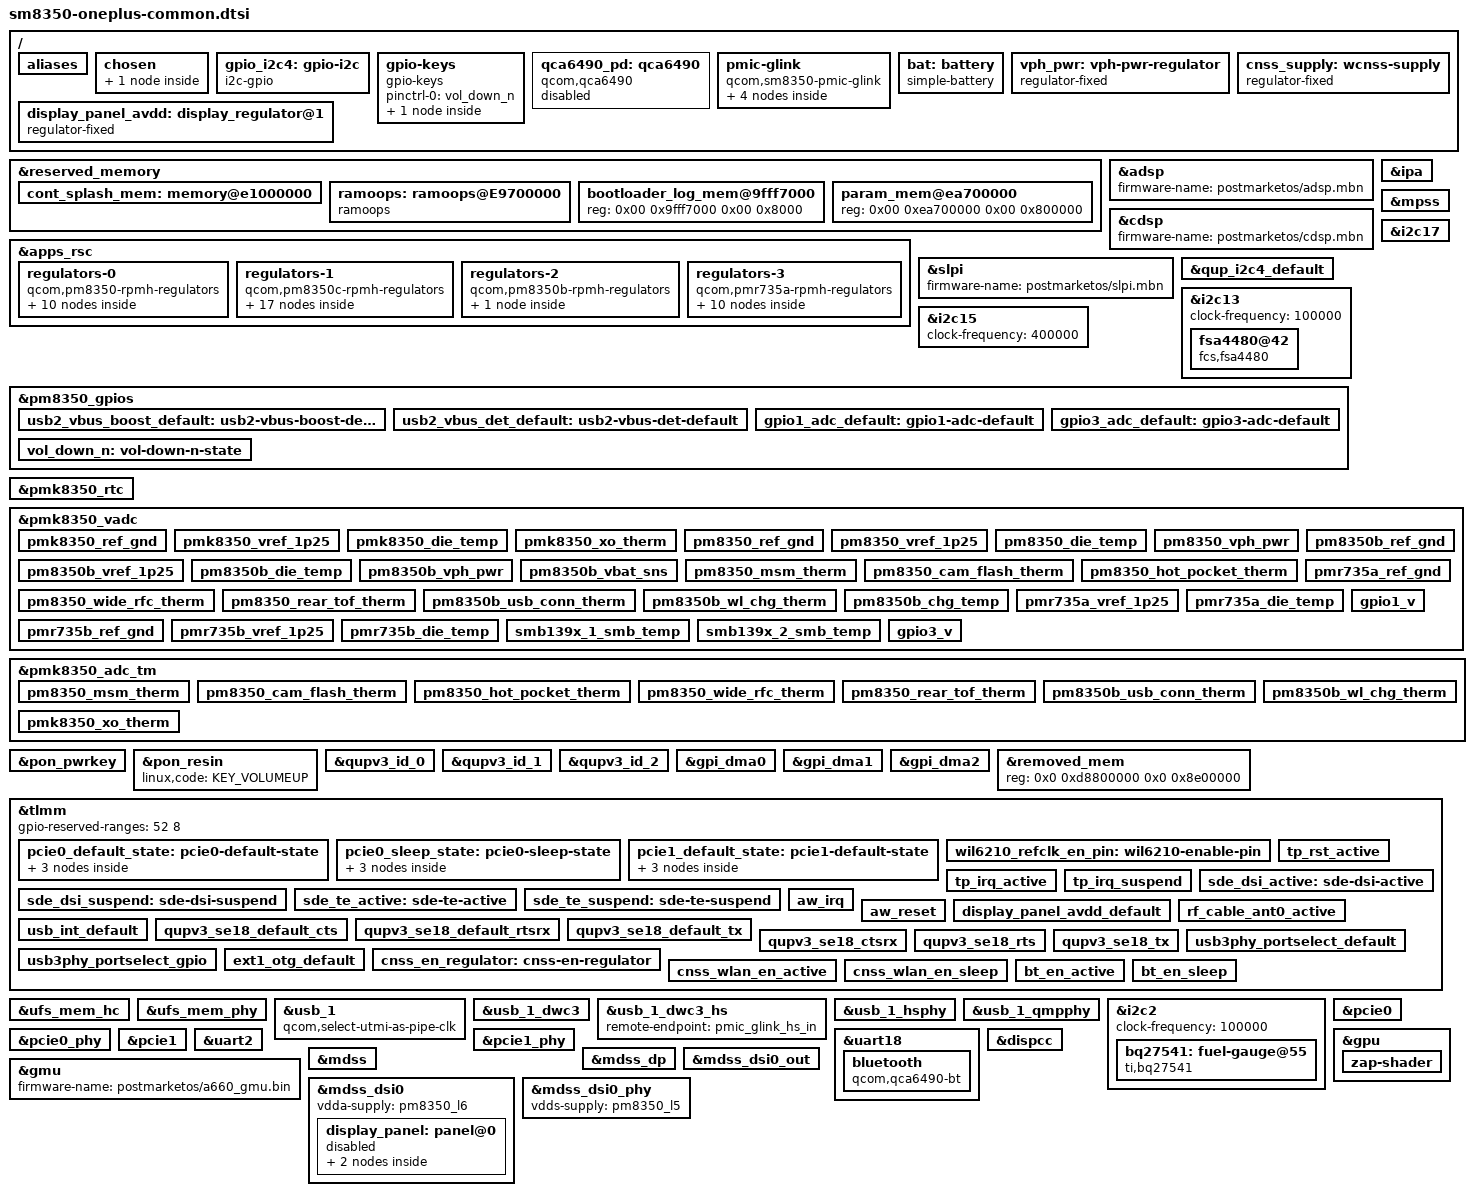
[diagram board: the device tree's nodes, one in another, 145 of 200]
// SPDX-License-Identifier: BSD-3-Clause
/*
 * Copyright (c) 2023 Nia Espera <nespera@igalia.com>
 * Copyright (c) 2023 Caleb Connolly <caleb.connolly@linaro.org>
 */

#include <dt-bindings/iio/qcom,spmi-adc7-pm8350.h>
#include <dt-bindings/iio/qcom,spmi-adc7-pm8350b.h>
#define SMB139x_1_SID 0x0b
#define SMB139x_2_SID 0x0c
#include <dt-bindings/iio/qcom,spmi-adc7-smb139x.h>
#include <dt-bindings/pinctrl/qcom,pmic-gpio.h>
#include <dt-bindings/regulator/qcom,rpmh-regulator.h>
#include "sm8350.dtsi"
#include "pm8350.dtsi"
#include "pm8350b.dtsi"
#include "pm8350c.dtsi"
#include "pmk8350.dtsi"
#include "pmr735a.dtsi"
#include "pmr735b.dtsi"

/ {
	/* As with the Sony devices, msm-id and board-id aren't needed here */
	chassis-type = "handset";
	interrupt-parent = <&intc>;

	aliases {
		bluetooth0 = &bluetooth;
		serial0 = &uart2;
		serial1 = &uart18;
	};

	/*
	 * Enabling framebuffer ends up messing with the display driver; only
	 * do so as needed per device. Keeping here and not in lemonade dts as
	 * it may be needed for the 9RT.
	 */

	chosen {
		#address-cells = <2>;
		#size-cells = <2>;
		ranges;

		framebuffer: framebuffer@e4d00000 {
			compatible = "simple-framebuffer";
			reg = <0 0xe4d00000 0 0x2400000>;
			width = <1080>;
			height = <2412>;
			stride = <(1080 * 4)>;
			format = "a8r8g8b8";
			/*
			 * That's (going to be) a lot of clocks, but it's
			 * necessary due to unused clk cleanup & no panel
			 * driver if this is enabled.
			 */
			clocks = <&gcc GCC_DISP_HF_AXI_CLK>,
				 <&gcc GCC_DISP_SF_AXI_CLK>;

			status = "disabled";
		};
	};

	gpio_i2c4: gpio-i2c {
		compatible = "i2c-gpio";
		sda-gpios = <&tlmm 20 (GPIO_ACTIVE_HIGH|GPIO_OPEN_DRAIN)>;
		scl-gpios = <&tlmm 21 (GPIO_ACTIVE_HIGH|GPIO_OPEN_DRAIN)>;
		#address-cells = <1>;
		#size-cells = <0>;

		pinctrl-names = "default";
		pinctrl-0 = <&qup_i2c4_default &tp_enable_2v8>;
	};

	gpio-keys {
		compatible = "gpio-keys";

		pinctrl-names = "default";
		pinctrl-0 = <&vol_down_n>;

		key-vol-up {
			label = "Volume Up";
			linux,code = <KEY_VOLUMEUP>;
			gpios = <&pmk8350_gpios 6 GPIO_ACTIVE_LOW>;
			debounce-interval = <15>;
			linux,can-disable;
			wakeup-source;
		};
	};

	qca6490_pd: qca6490 {
		compatible = "qcom,qca6490";
		#power-domain-cells = <0>;

		vddaonbt-supply = <&pm8350_s11>;
		vddaonwl-supply = <&pmr735a_s2>;
		vddasd-supply = <&pmr735a_l7>;
		vddrfa1-supply = <&pm8350c_s1>;
		vddrfa2-supply = <&pm8350_s12>;
		vddrfa3-supply = <&pm8350c_s1>;
		vddpcie1-supply = <&cnss_supply>;
		vddpcie2-supply = <&pm8350c_s1>;
		vddio-supply = <&pm8350_s10>;

		status = "disabled";
	};

	/* Unclear if this works currently, need to test */
	pmic-glink {
		compatible = "qcom,sm8350-pmic-glink", "qcom,pmic-glink";
		#address-cells = <1>;
		#size-cells = <0>;

		connector@0 {
			compatible = "usb-c-connector";
			reg = <0>;
			power-role = "dual";
			data-role = "dual";

			ports {
				#address-cells = <1>;
				#size-cells = <0>;

				port@0 {
					reg = <0>;

					pmic_glink_hs_in: endpoint {
						remote-endpoint = <&usb_1_dwc3_hs>;
					};
				};
				/*
				port@1 {
					reg = <1>;

					pmic_glink_ss_in: endpoint {
						remote-endpoint = <&usb_1_dwc3_ss>;
					};
				};
				*/
			};
		};
	};

	bat: battery {
		compatible = "simple-battery";
		device-chemistry = "lithium-ion";
		/* Wait for temp sensors to be enabled too before enabling */
		/*
		operating-range-celsius = <(-20) 60>;
		ambient-celsius = <(-3) 40>;
		*/
		voltage-min-design-microvolt = <3200000>;
		energy-full-design-microwatt-hours = <15840000>;
		charge-full-design-microamp-hours = <2225000>;
	};

	vph_pwr: vph-pwr-regulator {
		compatible = "regulator-fixed";
		regulator-name = "vph_pwr";
		regulator-min-microvolt = <3700000>;
		regulator-max-microvolt = <3700000>;

		regulator-always-on;
		regulator-boot-on;
	};

	cnss_supply: wcnss-supply {
		compatible = "regulator-fixed";
		regulator-name = "wcnss_regulator";
		regulator-min-microvolt = <1900000>;
		regulator-max-microvolt = <1900000>;

		enable-active-high;
		pinctrl-names = "default";
		pinctrl-0 = <&cnss_en_regulator>;
		gpio = <&tlmm 201 GPIO_ACTIVE_HIGH>;
	};

	/* Regulators needed for display bringup */
	display_panel_avdd: display_regulator@1 {
		compatible = "regulator-fixed";
		regulator-name = "display_panel_avdd";
		regulator-min-microvolt = <5500000>;
		regulator-max-microvolt = <5500000>;
		regulator-enable-ramp-delay = <233>;

		enable-active-high;
		regulator-boot-on;
		proxy-supply = <&display_panel_avdd>;
	};
	/*
	panel_supply_0: panel-supply-entry@0 {
		reg = <0>;
		compatible = "regulator-fixed";
		regulator-name = "vddio";
		regulator-min-voltage = <1800000>;
		regulator-max-voltage = <1800000>;
		qcom,supply-enable-load = <60700>;
		qcom,supply-disable-load = <80>;
		qcom,supply-post-on-sleep = <0>;
	};

	panel_supply_1: panel-supply-entry@1 {
		reg = <1>;
		compatible = "regulator-fixed";
		regulator-name = "vdd";
		regulator-min-voltage = <3200000>;
		regulator-max-voltage = <3200000>;
		qcom,supply-enable-load = <10000>;
		qcom,supply-disable-load = <0>;
		qcom,supply-post-on-sleep = <0>;
	};

	panel_supply_2: panel-supply-entry@2 {
		reg = <2>;
		compatible = "regulator-fixed";
		regulator-name = "lab";
		regulator-min-voltage = <4600000>;
		regulator-max-voltage = <6000000>;
		qcom,supply-enable-load = <0>;
		qcom,supply-disable-load = <0>;
	};

	panel_supply_3: panel-supply-entry@3 {
		reg = <3>;
		compatible = "regulator-fixed";
		regulator-name = "ibb";
		regulator-min-voltage = <4600000>;
		regulator-max-voltage = <6000000>;
		qcom,supply-enable-load = <0>;
		qcom,supply-disable-load = <0>;
		qcom,supply-post-on-sleep = <0>;
	};
	*/
};

&reserved_memory {
	cont_splash_mem: memory@e1000000 {
		reg = <0 0xe4d00000 0 0x02400000>;
		no-map;
		label = "cont_splash_region";
	};

	ramoops: ramoops@E9700000 {
		compatible = "ramoops";
		reg = <0 0xe9700000 0 0x05b8000>;
		record-size =	<0x40000>;
		console-size =	<0x40000>;
		ftrace-size =	<0x200000>;
		pmsg-size =	<0x200000>;
		devinfo-size =	<0x08000>;
		dumpinfo-size =	<0x08000>;
		rsv01info-size=	<0x08000>;
		rsv02info-size=	<0x08000>;
		rsv03info-size=	<0x08000>;
		rsv04info-size=	<0x08000>;
		rsv05info-size=	<0x08000>;
		ecc-size=	<0x0>;
	};

	bootloader_log_mem@9fff7000 {
		reg = <0x00 0x9fff7000 0x00 0x8000>;
	};

	param_mem@ea700000 {
		reg = <0x00 0xea700000 0x00 0x800000>;
	};
	/*
	modem_memshare {
		compatible = "shared-dma-pool";
		no-map;
	*/
		/*
		 * Memory shared with modem needs to be outside of the CLADE
		 * address space, which begins at 0xE0000000 and spans 512 MB.
		 *
		 * Unclear if this is supported upstream for now, so disabling.
		 */
	/*
		alloc-ranges = <0x0 0x00000000 0x0 0xdfffffff>;
		alignment = <0x0 0x100000>;
		size = <0x0 0x800000>;
	};
	*/
};

&apps_rsc {
	regulators-0 {
		compatible = "qcom,pm8350-rpmh-regulators";
		qcom,pmic-id = "b";

		vdd-s1-supply = <&vph_pwr>;
		vdd-s2-supply = <&vph_pwr>;
		vdd-s3-supply = <&vph_pwr>;
		vdd-s4-supply = <&vph_pwr>;
		vdd-s5-supply = <&vph_pwr>;
		vdd-s6-supply = <&vph_pwr>;
		vdd-s7-supply = <&vph_pwr>;
		vdd-s8-supply = <&vph_pwr>;
		vdd-s9-supply = <&vph_pwr>;
		vdd-s10-supply = <&vph_pwr>;
		vdd-s11-supply = <&vph_pwr>;
		vdd-s12-supply = <&vph_pwr>;

		vdd-l1-l4-supply = <&pm8350_s11>;
		vdd-l2-l7-supply = <&vreg_bob>;
		vdd-l3-l5-supply = <&vreg_bob>;
		vdd-l6-l9-l10-supply = <&pm8350_s11>;
		vdd-l8-supply = <&pmr735a_s2>;

		/*
		 * ARC regulators:
		 * S5 - mx.lvl
		 * S6 - gfx.lvl
		 * S9 - mxc.lvl
		 */

		pm8350_s10: smps10 {
			regulator-name = "pm8350_s10";
			regulator-min-microvolt = <1800000>;
			regulator-max-microvolt = <1800000>;
			regulator-initial-mode = <RPMH_REGULATOR_MODE_HPM>;
		};

		pm8350_s11: smps11 {
			regulator-name = "pm8350_s11";
			regulator-min-microvolt = <752000>;
			regulator-max-microvolt = <1012000>;
			regulator-initial-mode = <RPMH_REGULATOR_MODE_HPM>;
		};

		pm8350_s12: smps12 {
			regulator-name = "pm8350_s12";
			regulator-min-microvolt = <1224000>;
			regulator-max-microvolt = <1360000>;
			regulator-initial-mode = <RPMH_REGULATOR_MODE_HPM>;
		};

		pm8350_l1: ldo1 {
			regulator-name = "pm8350_l1";
			regulator-min-microvolt = <912000>;
			regulator-max-microvolt = <920000>;
			regulator-initial-mode = <RPMH_REGULATOR_MODE_HPM>;
		};

		pm8350_l2: ldo2 {
			regulator-name = "pm8350_l2";
			regulator-min-microvolt = <3072000>;
			regulator-max-microvolt = <3072000>;
			regulator-initial-mode = <RPMH_REGULATOR_MODE_HPM>;
		};

		pm8350_l3: ldo3 {
			regulator-name = "pm8350_l3";
			regulator-min-microvolt = <904000>;
			regulator-max-microvolt = <904000>;
			regulator-initial-mode = <RPMH_REGULATOR_MODE_HPM>;
		};

		/* L4 - lmx.lvl (ARC) */

		pm8350_l5: ldo5 {
			regulator-name = "pm8350_l5";
			regulator-min-microvolt = <880000>;
			regulator-max-microvolt = <888000>;
			regulator-initial-mode = <RPMH_REGULATOR_MODE_HPM>;
			regulator-allow-set-load;
			regulator-allowed-modes = <RPMH_REGULATOR_MODE_LPM
						   RPMH_REGULATOR_MODE_HPM>;
		};

		pm8350_l6: ldo6 {
			regulator-name = "pm8350_l6";
			regulator-min-microvolt = <1200000>;
			regulator-max-microvolt = <1208000>;
			regulator-initial-mode = <RPMH_REGULATOR_MODE_HPM>;
			regulator-allow-set-load;
			regulator-allowed-modes = <RPMH_REGULATOR_MODE_LPM
						   RPMH_REGULATOR_MODE_HPM>;
		};

		pm8350_l7: ldo7 {
			regulator-name = "pm8350_l7";
			regulator-min-microvolt = <2400000>;
			regulator-max-microvolt = <3008000>;
			regulator-initial-mode = <RPMH_REGULATOR_MODE_HPM>;
			regulator-allow-set-load;
			regulator-allowed-modes = <RPMH_REGULATOR_MODE_LPM
						   RPMH_REGULATOR_MODE_HPM>;
		};

		/* L8 - lcx.lvl (ARC) */

		pm8350_l9: ldo9 {
			regulator-name = "pm8350_l9";
			regulator-min-microvolt = <1200000>;
			regulator-max-microvolt = <1200000>;
			regulator-initial-mode = <RPMH_REGULATOR_MODE_HPM>;
			regulator-allow-set-load;
			regulator-allowed-modes = <RPMH_REGULATOR_MODE_LPM
						   RPMH_REGULATOR_MODE_HPM>;
		};
	};

	regulators-1 {
		compatible = "qcom,pm8350c-rpmh-regulators";
		qcom,pmic-id = "c";

		vdd-s1-supply = <&vph_pwr>;
		vdd-s2-supply = <&vph_pwr>;
		vdd-s3-supply = <&vph_pwr>;
		vdd-s4-supply = <&vph_pwr>;
		vdd-s5-supply = <&vph_pwr>;
		vdd-s6-supply = <&vph_pwr>;
		vdd-s7-supply = <&vph_pwr>;
		vdd-s8-supply = <&vph_pwr>;
		vdd-s9-supply = <&vph_pwr>;
		vdd-s10-supply = <&vph_pwr>;

		vdd-l1-l12-supply = <&pm8350c_s1>;
		vdd-l2-l8-supply = <&pm8350c_s1>;
		vdd-l3-l4-l5-l7-l13-supply = <&vreg_bob>;
		vdd-l6-l9-l11-supply = <&vreg_bob>;
		vdd-l10-supply = <&pm8350_s12>;

		vdd-bob-supply = <&vph_pwr>;

		pm8350c_s1: smps1 {
			regulator-name = "pm8350c_s1";
			regulator-min-microvolt = <1800000>;
			regulator-max-microvolt = <1952000>;
			regulator-initial-mode = <RPMH_REGULATOR_MODE_HPM>;
		};

		/* S2 - ebi.lvl (ARC) */

		pm8350c_s3: smps3 {
			regulator-name = "pm8350c_s3";
			regulator-min-microvolt = <300000>;
			regulator-max-microvolt = <704000>;
			regulator-initial-mode = <RPMH_REGULATOR_MODE_HPM>;
		};

		/*
		 * ARC regulators:
		 * S4 - mss.lvl
		 * S6 - cx.lvl
		 * S8 - mmcx.lvl
		 */

		pm8350c_s10: smps10 {
			regulator-name = "pm8350c_s10";
			regulator-min-microvolt = <1048000>;
			regulator-max-microvolt = <1128000>;
			regulator-initial-mode = <RPMH_REGULATOR_MODE_HPM>;
		};

		pm8350c_l1: ldo1 {
			regulator-name = "pm8350c_l1";
			regulator-min-microvolt = <1800000>;
			regulator-max-microvolt = <1800000>;
			regulator-initial-mode = <RPMH_REGULATOR_MODE_HPM>;
		};

		pm8350c_l2: ldo2 {
			regulator-name = "pm8350c_l2";
			regulator-min-microvolt = <1800000>;
			regulator-max-microvolt = <1800000>;
			regulator-initial-mode = <RPMH_REGULATOR_MODE_HPM>;
		};

		pm8350c_l3: ldo3 {
			regulator-name = "pm8350c_l3";
			regulator-min-microvolt = <3000000>;
			regulator-max-microvolt = <3300000>;
			regulator-initial-mode = <RPMH_REGULATOR_MODE_HPM>;
		};

		pm8350c_l4: ldo4 {
			regulator-name = "pm8350c_l4";
			regulator-min-microvolt = <1704000>;
			regulator-max-microvolt = <3000000>;
			regulator-initial-mode = <RPMH_REGULATOR_MODE_HPM>;
		};

		pm8350c_l5: ldo5 {
			regulator-name = "pm8350c_l5";
			regulator-min-microvolt = <1704000>;
			regulator-max-microvolt = <3000000>;
			regulator-initial-mode = <RPMH_REGULATOR_MODE_HPM>;
		};

		pm8350c_l6: ldo6 {
			regulator-name = "pm8350c_l6";
			regulator-min-microvolt = <1800000>;
			regulator-max-microvolt = <2960000>;
			regulator-initial-mode = <RPMH_REGULATOR_MODE_HPM>;
		};

		pm8350c_l7: ldo7 {
			regulator-name = "pm8350c_l7";
			regulator-min-microvolt = <3008000>;
			regulator-max-microvolt = <3008000>;
			regulator-initial-mode = <RPMH_REGULATOR_MODE_HPM>;
		};

		pm8350c_l8: ldo8 {
			regulator-name = "pm8350c_l8";
			regulator-min-microvolt = <1800000>;
			regulator-max-microvolt = <1800000>;
			regulator-initial-mode = <RPMH_REGULATOR_MODE_HPM>;
		};

		pm8350c_l9: ldo9 {
			regulator-name = "pm8350c_l9";
			regulator-min-microvolt = <2800000>;
			regulator-max-microvolt = <3008000>;
			regulator-initial-mode = <RPMH_REGULATOR_MODE_HPM>;
		};

		pm8350c_l10: ldo10 {
			regulator-name = "pm8350c_l10";
			regulator-min-microvolt = <1200000>;
			regulator-max-microvolt = <1200000>;
			regulator-initial-mode = <RPMH_REGULATOR_MODE_HPM>;
		};

		pm8350c_l11: ldo11 {
			regulator-name = "pm8350c_l11";
			regulator-min-microvolt = <2400000>;
			regulator-max-microvolt = <3008000>;
			regulator-initial-mode = <RPMH_REGULATOR_MODE_HPM>;
		};

		pm8350c_l12: ldo12 {
			regulator-name = "pm8350c_l12";
			regulator-min-microvolt = <1800000>;
			regulator-max-microvolt = <2000000>;
			regulator-initial-mode = <RPMH_REGULATOR_MODE_HPM>;
		};

		pm8350c_l13: ldo13 {
			regulator-name = "pm8350c_l13";
			regulator-min-microvolt = <3000000>;
			regulator-max-microvolt = <3200000>;
			regulator-initial-mode = <RPMH_REGULATOR_MODE_HPM>;
		};

		vreg_bob: bob {
			regulator-name = "vreg_bob";
			regulator-min-microvolt = <3400000>;
			regulator-max-microvolt = <3960000>;
			regulator-initial-mode = <RPMH_REGULATOR_MODE_AUTO>;
		};
	};

	regulators-2 {
		compatible = "qcom,pm8350b-rpmh-regulators";
		qcom,pmic-id = "d";

		vdd-l1-supply = <&pm8350_s12>;

		pm8350b_l1: ldo1 {
			regulator-name = "pm8350b_l1";
			regulator-min-microvolt = <1200000>;
			regulator-max-microvolt = <1200000>;
			regulator-initial-mode = <RPMH_REGULATOR_MODE_HPM>;
			regulator-allowed-modes = <RPMH_REGULATOR_MODE_LPM
						   RPMH_REGULATOR_MODE_HPM>;
		};
	};

	regulators-3 {
		compatible = "qcom,pmr735a-rpmh-regulators";
		qcom,pmic-id = "e";

		vdd-s1-supply = <&vph_pwr>;
		vdd-s2-supply = <&vph_pwr>;
		vdd-s3-supply = <&vph_pwr>;

		vdd-l1-l2-supply = <&pmr735a_s2>;
		vdd-l3-supply = <&pmr735a_s1>;
		vdd-l4-supply = <&pm8350c_s1>;
		vdd-l5-l6-supply = <&pm8350c_s1>;
		vdd-l7-bob-supply = <&vreg_bob>;

		pmr735a_s1: smps1 {
			regulator-name = "pmr735a_s1";
			regulator-min-microvolt = <1200000>;
			regulator-max-microvolt = <1280000>;
		};

		pmr735a_s2: smps2 {
			regulator-name = "pmr735a_s2";
			regulator-min-microvolt = <500000>;
			regulator-max-microvolt = <976000>;
		};

		pmr735a_s3: smps3 {
			regulator-name = "pmr735a_s3";
			regulator-min-microvolt = <2208000>;
			regulator-max-microvolt = <2352000>;
		};

		pmr735a_l1: ldo1 {
			regulator-name = "pmr735a_l1";
			regulator-min-microvolt = <912000>;
			regulator-max-microvolt = <912000>;
		};

		pmr735a_l2: ldo2 {
			regulator-name = "pmr735a_l2";
			regulator-min-microvolt = <1200000>;
			regulator-max-microvolt = <1200000>;
		};

		pmr735a_l3: ldo3 {
			regulator-name = "pmr735a_l3";
			regulator-min-microvolt = <1200000>;
			regulator-max-microvolt = <1200000>;
		};

		pmr735a_l4: ldo4 {
			regulator-name = "pmr735a_l4";
			regulator-min-microvolt = <1776000>;
			regulator-max-microvolt = <1872000>;
		};

		pmr735a_l5: ldo5 {
			regulator-name = "pmr735a_l5";
			regulator-min-microvolt = <800000>;
			regulator-max-microvolt = <800000>;
		};

		pmr735a_l6: ldo6 {
			regulator-name = "pmr735a_l6";
			regulator-min-microvolt = <480000>;
			regulator-max-microvolt = <904000>;
		};

		pmr735a_l7: ldo7 {
			regulator-name = "pmr735a_l7";
			regulator-min-microvolt = <2800000>;
			regulator-max-microvolt = <2800000>;
			regulator-initial-mode = <RPMH_REGULATOR_MODE_HPM>;
			regulator-allowed-modes = <RPMH_REGULATOR_MODE_LPM
						   RPMH_REGULATOR_MODE_HPM>;
		};
	};
};
/*
 * Build in remoteproc & IPA drivers as modules or load the fw into the kernel;
 * otherwise, it attempts to load the fw too soon, errors, and never tries again.
 */
&adsp {
	firmware-name = "postmarketos/adsp.mbn";
	status = "okay";
};

&cdsp {
	firmware-name = "postmarketos/cdsp.mbn";
	status = "okay";
};

&slpi {
	firmware-name = "postmarketos/slpi.mbn";
	status = "okay";
};

&ipa {
	qcom,gsi-loader = "self";
	memory-region = <&pil_ipa_fw_mem>;
	firmware-name = "postmarketos/ipa_fws.mbn";
	status = "okay";
};

&mpss {
	firmware-name = "postmarketos/modem.mbn",
			"postmarketos/mcfg_hw.mbn";

	status = "okay";
};

//&i2c4 {
	/* Touchscreens live here */
//	clock-frequency = <400000>;
//	status = "okay";
//};

&qup_i2c4_default {
	function = "gpio";
	bias-disable;
};

&i2c13 {
	clock-frequency = <100000>;
	status = "okay";

	fsa4480@42 {
		compatible = "fcs,fsa4480";
		reg = <0x42>;
		mode-switch;
		orientation-switch;
	};

	/* Qualcomm PM8008i/PM8008j (?) @ 8, 9, c, d */
};

&i2c15 {
	clock-frequency = <400000>;
	status = "okay";

	/*
	 * The OnePlus 9 uses a pair of hall sensors for the
	 * tri-state key UP and DOWN detection, one of the
	 * following variants:
	 *
	 * ist8801 hall sensor @ 18, 19
	 * MagnaChip MXM1120 hall sensor @ 0C, 0D
	 */

	/* sn-nci NFC controller @ 28 */
};

&i2c17 {
	//clock-frequency = <10000>;
	//status = "okay";

	/* Awinic aw8697 haptics driver @ 5A */
};

&pm8350_gpios {
	usb2_vbus_boost_default: usb2-vbus-boost-default {
		pins = "gpio8";
		function = "normal";
		output-low;
		power-source = <0x00>;
	};

	usb2_vbus_det_default: usb2-vbus-det-default {
		pins = "gpio9";
		function = "normal";
		input-enable;
		bias-disable;
		power-source = <0x00>;
	};

	gpio1_adc_default: gpio1-adc-default {
		pins = "gpio1";
		function = "normal";
		bias-high-impedance;
		bias-disable;
	};

	gpio3_adc_default: gpio3-adc-default {
		pins = "gpio3";
		function = "normal";
		bias-high-impedance;
		bias-disable;
	};
};

&pm8350_gpios {
	/* This (or something related) errors but still seems to work */
	vol_down_n: vol-down-n-state {
		pins = "gpio6";
		function = "normal";
		power-source = <1>;
		bias-pull-up;
		input-enable;
	};
};

&pmk8350_rtc {
	status = "okay";
};

&pmk8350_vadc {
	pinctrl-0 = <&gpio1_adc_default &gpio1_adc_default>;
	pinctrl-names = "default";

	pmk8350_ref_gnd {
		reg = <0x00>;
		label = "pmk8350_ref_gnd";
		qcom,pre-scaling = <0x01 0x01>;
	};

	pmk8350_vref_1p25 {
		reg = <0x01>;
		label = "pmk8350_vref_1p25";
		qcom,pre-scaling = <0x01 0x01>;
	};

	pmk8350_die_temp {
		reg = <0x03>;
		label = "pmk8350_die_temp";
		qcom,pre-scaling = <0x01 0x01>;
	};

	pmk8350_xo_therm {
		reg = <0x44>;
		label = "pmk8350_xo_therm";
		qcom,ratiometric;
		qcom,hw-settle-time = <0xc8>;
		qcom,pre-scaling = <0x01 0x01>;
	};

	pm8350_ref_gnd {
		reg = <0x100>;
		label = "pm8350_ref_gnd";
		qcom,pre-scaling = <0x01 0x01>;
	};

	pm8350_vref_1p25 {
		reg = <0x101>;
		label = "pm8350_vref_1p25";
		qcom,pre-scaling = <0x01 0x01>;
	};

	pm8350_die_temp {
		reg = <0x103>;
		label = "pm8350_die_temp";
		qcom,pre-scaling = <0x01 0x01>;
	};

	pm8350_vph_pwr {
		reg = <0x18e>;
		label = "pm8350_vph_pwr";
		qcom,pre-scaling = <0x01 0x03>;
	};

	pm8350b_ref_gnd {
		reg = <0x300>;
		label = "pm8350b_ref_gnd";
		qcom,pre-scaling = <0x01 0x01>;
	};

	pm8350b_vref_1p25 {
		reg = <0x301>;
		label = "pm8350b_vref_1p25";
		qcom,pre-scaling = <0x01 0x01>;
	};

	pm8350b_die_temp {
		reg = <0x303>;
		label = "pm8350b_die_temp";
		qcom,pre-scaling = <0x01 0x01>;
	};

	pm8350b_vph_pwr {
		reg = <0x38e>;
		label = "pm8350b_vph_pwr";
		qcom,pre-scaling = <0x01 0x03>;
	};

	pm8350b_vbat_sns {
		reg = <0x38f>;
		label = "pm8350b_vbat_sns";
		qcom,pre-scaling = <0x01 0x03>;
	};

	pm8350_msm_therm {
		reg = <PM8350_ADC7_AMUX_THM1_100K_PU(1)>;
		label = "pm8350_msm_therm";
		qcom,ratiometric;
		qcom,hw-settle-time = <200>;
		qcom,pre-scaling = <1 1>;
	};

	pm8350_cam_flash_therm {
		reg = <PM8350_ADC7_AMUX_THM2_100K_PU(1)>;
		label = "pm8350_cam_flash_therm";
		qcom,ratiometric;
		qcom,hw-settle-time = <200>;
		qcom,pre-scaling = <1 1>;
	};

	pm8350_hot_pocket_therm {
		reg = <PM8350_ADC7_AMUX_THM3_100K_PU(1)>;
		label = "pm8350_hot_pocket_therm";
		qcom,ratiometric;
		qcom,hw-settle-time = <200>;
		qcom,pre-scaling = <1 1>;
	};

	pm8350_wide_rfc_therm {
		reg = <PM8350_ADC7_AMUX_THM4_100K_PU(1)>;
		label = "pm8350_wide_rfc_therm";
		qcom,ratiometric;
		qcom,hw-settle-time = <200>;
		qcom,pre-scaling = <1 1>;
	};

	pm8350_rear_tof_therm {
		reg = <PM8350_ADC7_AMUX_THM5_100K_PU(1)>;
		label = "pm8350_rear_tof_therm";
		qcom,ratiometric;
		qcom,hw-settle-time = <200>;
		qcom,pre-scaling = <1 1>;
	};

	pm8350b_usb_conn_therm {
		reg = <PM8350B_ADC7_AMUX_THM4_100K_PU>;
		label = "pm8350b_usb_conn_therm";
		qcom,ratiometric;
		qcom,hw-settle-time = <200>;
		qcom,pre-scaling = <1 1>;
	};

	pm8350b_wl_chg_therm {
		reg = <PM8350B_ADC7_GPIO2_100K_PU>;
		label = "pm8350b_wl_chg_therm";
		qcom,ratiometric;
		qcom,hw-settle-time = <200>;
		qcom,pre-scaling = <1 1>;
	};

	pm8350b_chg_temp {
		reg = <PM8350B_ADC7_CHG_TEMP>;
		label = "pm8350b_chg_temp";
		qcom,pre-scaling = <1 1>;
	};
	/*
	pm8350b_iin_fb {
		reg = <PM8350B_ADC7_IIN_FB>;
		label = "pm8350b_iin_fb";
		qcom,pre-scaling = <32 100>;
	};

	pm8350b_ichg_fb {
		reg = <PM8350B_ADC7_ICHG_FB>;
		label = "pm8350b_ichg_fb";
		qcom,pre-scaling = <1000 305185>;
	};
	*/
	pmr735a_ref_gnd {
		reg = <0x400>;
		label = "pmr735a_ref_gnd";
		qcom,pre-scaling = <0x01 0x01>;
	};

	pmr735a_vref_1p25 {
		reg = <0x401>;
		label = "pmr735a_vref_1p25";
		qcom,pre-scaling = <0x01 0x01>;
	};

	pmr735a_die_temp {
		reg = <0x403>;
		label = "pmr735a_die_temp";
		qcom,pre-scaling = <0x01 0x01>;
	};

	pmr735b_ref_gnd {
		reg = <0x500>;
		label = "pmr735b_ref_gnd";
		qcom,pre-scaling = <0x01 0x01>;
	};

	pmr735b_vref_1p25 {
		reg = <0x501>;
		label = "pmr735b_vref_1p25";
		qcom,pre-scaling = <0x01 0x01>;
	};

	pmr735b_die_temp {
		reg = <0x503>;
		label = "pmr735b_die_temp";
		qcom,pre-scaling = <0x01 0x01>;
	};

	smb139x_1_smb_temp {
		reg = <SMB139x_1_ADC7_SMB_TEMP>;
		label = "smb139x_1_smb_temp";
		qcom,pre-scaling = <1 1>;
	};
	/*
	smb139x_1_ichg_smb {
		reg = <SMB139x_1_ADC7_ICHG_SMB>;
		label = "smb139x_1_ichg_smb";
		qcom,pre-scaling = <16 100>;
	};

	smb139x_1_iin_smb {
		reg = <SMB139x_1_ADC7_IIN_SMB>;
		label = "smb139x_1_iin_smb";
		qcom,pre-scaling = <32 100>;
	};
	*/
	smb139x_2_smb_temp {
		reg = <SMB139x_2_ADC7_SMB_TEMP>;
		label = "smb139x_2_smb_temp";
		qcom,pre-scaling = <1 1>;
	};
	/*
	smb139x_2_ichg_smb {
		reg = <SMB139x_2_ADC7_ICHG_SMB>;
		label = "smb139x_2_ichg_smb";
		qcom,pre-scaling = <16 100>;
	};

	smb139x_2_iin_smb {
		reg = <SMB139x_2_ADC7_IIN_SMB>;
		label = "smb139x_2_iin_smb";
		qcom,pre-scaling = <32 100>;
	};
	*/
	gpio1_v {
		reg = <0x128>;
		label = "gpio1_v";
		qcom,ratiometric;
		qcom,hw-settle-time = <0x2bc>;
		qcom,pre-scaling = <0x01 0x01>;
	};

	gpio3_v {
		reg = <0x12b>;
		label = "gpio3_v";
		qcom,ratiometric;
		qcom,hw-settle-time = <0x2bc>;
		qcom,pre-scaling = <0x01 0x01>;
	};
};

&pmk8350_adc_tm {
	status = "okay";

	pm8350_msm_therm {
		reg = <0x144>;
		qcom,ratiometric;
		qcom,hw-settle-time = <0xc8>;
	};

	pm8350_cam_flash_therm {
		reg = <0x145>;
		qcom,ratiometric;
		qcom,hw-settle-time = <0xc8>;
	};

	pm8350_hot_pocket_therm {
		reg = <0x146>;
		qcom,ratiometric;
		qcom,hw-settle-time = <0xc8>;
	};

	pm8350_wide_rfc_therm {
		reg = <0x147>;
		qcom,ratiometric;
		qcom,hw-settle-time = <0xc8>;
	};

	pm8350_rear_tof_therm {
		reg = <0x148>;
		qcom,ratiometric;
		qcom,hw-settle-time = <0xc8>;
	};

	pm8350b_usb_conn_therm {
		reg = <0x347>;
		qcom,ratiometric;
		qcom,hw-settle-time = <0xc8>;
	};

	pm8350b_wl_chg_therm {
		reg = <0x34b>;
		qcom,ratiometric;
		qcom,hw-settle-time = <0xc8>;
	};

	pmk8350_xo_therm {
		reg = <0x44>;
		qcom,ratiometric;
		qcom,hw-settle-time = <0xc8>;
	};
};

&pon_pwrkey {
	status = "okay";
};

&pon_resin {
	linux,code = <KEY_VOLUMEUP>;
	status = "okay";
};

&qupv3_id_0 {
	status = "okay";
};

&qupv3_id_1 {
	status = "okay";
};

&qupv3_id_2 {
	status = "okay";
};

&gpi_dma0 {
	status = "okay"; /* Causes hang on boot if qupv3-0 i2cs are enabled */
};

&gpi_dma1 {
	status = "okay";
};

&gpi_dma2 {
	status = "okay";
};

&removed_mem {
	reg = <0x0 0xd8800000 0x0 0x8e00000>;
};

&tlmm {
	gpio-reserved-ranges = <52 8>;

	pcie0_default_state: pcie0-default-state {
		perst-pins {
			pins = "gpio94";
			function = "gpio";
			drive-strength = <2>;
			bias-pull-down;
		};

		clkreq-wake-pins {
			pins = "gpio95";
			function = "pcie0_clkreqn";
			drive-strength = <2>;
			bias-pull-up;
		};

		wake-pins {
			pins = "gpio96";
			function = "gpio";
			drive-strength = <2>;
			bias-pull-up;
		};
	};

	pcie0_sleep_state: pcie0-sleep-state {
		perst-pins {
			pins = "gpio94";
			function = "gpio";
			drive-strength = <2>;
			bias-pull-down;
		};

		clkreq-sleep-pins {
			pins = "gpio95";
			function = "gpio";
			drive-strength = <2>;
			bias-pull-up;
		};

		wake-pins {
			pins = "gpio96";
			function = "gpio";
			drive-strength = <2>;
			bias-pull-up;
		};
	};


	pcie1_default_state: pcie1-default-state {
		perst-pins {
			pins = "gpio97";
			function = "gpio";
			drive-strength = <2>;
			bias-pull-down;
		};

		clkreq-pins {
			pins = "gpio98";
			function = "pcie1_clkreqn";
			drive-strength = <2>;
			bias-pull-up;
		};

		wake-pins {
			pins = "gpio99";
			function = "gpio";
			drive-strength = <2>;
			bias-pull-up;
		};
	};

	wil6210_refclk_en_pin: wil6210-enable-pin {
		pins = "gpio67";
		function = "gpio";
		bias-pull-down;
		drive-strength = <2>;
	};

	tp_rst_active: tp_rst_active {
		pins = "gpio22";
		function = "gpio";
		drive-strength = <8>;
		bias-pull-up;
	};

	tp_irq_active: tp_irq_active {
		pins = "gpio23";
		function = "gpio";
		drive-strength = <8>;
		bias-disable;
		input-enable;
	};

	/* Only reset suspend pin is different */
	tp_irq_suspend: tp_irq_suspend {
		pins = "gpio23";
		function = "gpio";
		drive-strength = <2>;
		bias-pull-down;
	};

	sde_dsi_active: sde-dsi-active {
		pins = "gpio24";
		function = "gpio";
		drive-strength = <8>;
		bias-disable = <0>;
	};

	sde_dsi_suspend: sde-dsi-suspend {
		pins = "gpio24";
		function = "gpio";
		drive-strength = <2>;
		bias-pull-down;
	};

	sde_te_active: sde-te-active {
		pins = "gpio82";
		function = "mdp_vsync";
		drive-strength = <2>;
		bias-pull-down;
	};

	sde_te_suspend: sde-te-suspend {
		pins = "gpio82";
		function = "mdp_vsync";
		drive-strength = <2>;
		bias-pull-down;
	};

	aw_irq: aw_irq {
		pins = "gpio14";
		function = "gpio";
		drive-strength = <2>;
		bias-pull-up;
	};

	aw_reset: aw_reset {
		pins = "gpio75";
		function = "gpio";
		drive-strength = <2>;
		bias-disable;
	};

	display_panel_avdd_default: display_panel_avdd_default {
		pins = "gpio12";
		function = "gpio";
		drive-strength = <8>;
		bias-disable = <0>;
		output-high;
	};

	/* Modem-related pin common on both devices */
	rf_cable_ant0_active: rf_cable_ant0_active {
		pins = "gpio165";
		function = "gpio";
		drive-strength = <2>;
		bias-pull-up;
	};

	usb_int_default: usb_int_default {
		pins = "gpio198";
		function = "gpio";
		drive-strength = <2>;
		bias-pull-down;
		input-enable;
	};

	qupv3_se18_default_cts: qupv3_se18_default_cts {
		pins = "gpio68";
		function = "gpio";
		drive-strength = <2>;
		bias-disable;
	};

	qupv3_se18_default_rtsrx: qupv3_se18_default_rtsrx {
		pins = "gpio69", "gpio71";
		function = "gpio";
		drive-strength = <2>;
		bias-pull-down;
	};

	qupv3_se18_default_tx: qupv3_se18_default_tx {
		pins = "gpio70";
		function = "gpio";
		drive-strength = <2>;
		bias-pull-up;
	};

	qupv3_se18_ctsrx: qupv3_se18_ctsrx {
		pins = "gpio68", "gpio71";
		function = "qup18";
		drive-strength = <2>;
		bias-disable;
	};

	qupv3_se18_rts: qupv3_se18_rts {
		pins = "gpio69";
		function = "qup18";
		drive-strength = <2>;
		bias-pull-down;
	};

	qupv3_se18_tx: qupv3_se18_tx {
		pins = "gpio70";
		function = "qup18";
		drive-strength = <2>;
		bias-pull-up;
	};

	usb3phy_portselect_default: usb3phy_portselect_default {
		pins = "gpio81";
		function = "usb_phy";
		drive-strength = <2>;
		bias-disable;
	};

	usb3phy_portselect_gpio: usb3phy_portselect_gpio {
		pins = "gpio81";
		function = "gpio";
		drive-strength = <2>;
		bias-disable;
	};

	ext1_otg_default: ext1_otg_default {
		pins = "gpio8";
		function = "gpio";
		drive-strength = <16>;
		bias-pull-down;
		input-enable;
	};

	cnss_en_regulator: cnss-en-regulator {
		pins = "gpio201";
		function = "gpio";
		drive-strength = <16>;
		bias-pull-down;
		output-low;
	};

	cnss_wlan_en_active: cnss_wlan_en_active {
		pins = "gpio64";
		function = "gpio";
		drive-strength = <16>;
		output-low;
		bias-pull-up;
	};

	cnss_wlan_en_sleep: cnss_wlan_en_sleep {
		pins = "gpio64";
		function = "gpio";
		drive-strength = <2>;
		output-low;
		bias-pull-down;
	};

	bt_en_active: bt_en_active {
		pins = "gpio65";
		function = "gpio";
		drive-strength = <16>;
		output-high;
		bias-pull-up;
	};

	bt_en_sleep: bt_en_sleep {
		pins = "gpio65";
		function = "gpio";
		drive-strength = <2>;
		output-low;
		bias-pull-down;
	};
};

&ufs_mem_hc {
	reset-gpios = <&tlmm 203 GPIO_ACTIVE_LOW>;

	vcc-supply = <&pm8350_l7>;
	vcc-voltage-level = <2504000 2950000>;
	vcc-max-microamp = <800000>;
	vccq-supply = <&pm8350_l9>;
	vccq-max-microamp = <900000>;

	qcom,vddp-ref-clk-supply = <&pm8350_l9>;
	qcom,vddp-ref-clk-max-microamp = <100>;

	qcom,vddp-ref-clk-supply = <&pm8350_s12>;
	qcom,vccq-parent-max-microamp = <210000>;

	status = "okay";
};

&ufs_mem_phy {
	vdda-phy-supply = <&pm8350_l5>;
	vdda-phy-always-on;
	vdda-max-microamp = <91600>;
	vdda-pll-supply = <&pm8350_l6>;
	vdda-pll-max-microamp = <19000>;

	status = "okay";
};

&usb_1 {
	/* Interconnects on OP9(P) break the USB RPMh so we disable them for now */
	/delete-property/ interconnects;
	/delete-property/ interconnect-names;
	/* USB3 is not functional so limit to high-speed and disable it */
	qcom,select-utmi-as-pipe-clk;

	status = "okay";
};

&usb_1_dwc3 {
	/* Mode switching is untested; need to see if this can be set to "otg" */
	dr_mode = "peripheral";
	maximum-speed = "high-speed";
	phys = <&usb_1_hsphy>;
	phy-names = "usb2-phy";
};

&usb_1_dwc3_hs {
	remote-endpoint = <&pmic_glink_hs_in>;
};
/*
&usb_1_dwc3_ss {
	remote-endpoint = <&pmic_glink_ss_in>;
};
*/
&usb_1_hsphy {
	vdda-pll-supply = <&pm8350_l5>;
	vdda18-supply = <&pm8350c_l1>;
	vdda33-supply = <&pm8350_l2>;

	status = "okay";
};
/* Enabling this is necessary only for displayport */

&usb_1_qmpphy {
	vdda-phy-supply = <&pm8350_l6>;
	vdda-pll-supply = <&pm8350_l1>;

	status = "okay";
};

&i2c2 {
	clock-frequency = <100000>;
	status = "okay";

	bq27541: fuel-gauge@55 {
		compatible = "ti,bq27541";
		reg = <0x55>;
		monitored-battery = <&bat>;
	};
};

&pcie0 {
	pinctrl-names = "default", "sleep";
	pinctrl-0 = <&pcie0_default_state>;
	pinctrl-1 = <&pcie0_sleep_state>;

	perst-gpios = <&tlmm 94 GPIO_ACTIVE_LOW>;
	wake-gpios = <&tlmm 96 GPIO_ACTIVE_HIGH>;

	status = "okay";
};

&pcie0_phy {
	vdda-phy-supply = <&pm8350_l5>;
	vdda-pll-supply = <&pm8350_l6>;

	status = "okay";
};

&pcie1 {
	/* XXX: move wil6210 pin into its own thing */
	pinctrl-names = "default";
	pinctrl-0 = <&pcie1_default_state &wil6210_refclk_en_pin>;

	perst-gpios = <&tlmm 97 GPIO_ACTIVE_LOW>;
	wake-gpios = <&tlmm 99 GPIO_ACTIVE_HIGH>;

	status = "okay";
};

&pcie1_phy {
	vdda-phy-supply = <&pm8350_l5>;
	vdda-pll-supply = <&pm8350_l6>;
	power-domains = <&qca6490_pd>;

	status = "okay";
};

&uart2 {
	status = "okay";
};

&uart18 {
	status = "okay";

	bluetooth: bluetooth {
		compatible = "qcom,qca6490-bt";

		pinctrl-0 = <&bt_en_active>;
		pinctrl-1 = <&bt_en_sleep>;
		pinctrl-names = "default", "sleep";

		/* QCA6490 requires wlan and bluetooth be enabled simultaneously */
		enable-gpios = <&tlmm 65 GPIO_ACTIVE_HIGH>;
		wlan-gpios = <&tlmm 64 GPIO_ACTIVE_HIGH>;
		swctrl-gpios = <&tlmm 153 GPIO_ACTIVE_HIGH>;

		power-domains = <&qca6490_pd>;

		//vddio-supply = <&pm8350_s10>;
		//vddaon-supply = <&pm8350_s11>;
		//vddasd-supply = <&pmr735a_l7>;
		//vdddig-supply = <&pm8350_s11>;
		//vddrfa1-supply = <&pm8350c_s1>;
		//vddrfa2-supply = <&pm8350_s12>;
		//vddpcie1-supply = <&pm8350_s12>;
		//vddpcie2-supply = <&pm8350c_s1>;

		//dick = "balls";

		max-speed = <3200000>;

		//status = "disabled";
	};
};

/*
 * Everything beyond here and/or enabling gpucc/videocc/etc. drivers will lead
 * to simplefb being killed; either disable all or write a display driver.
 */
&gpu {
	status = "okay";

	zap-shader {
		memory-region = <&pil_gpu_mem>;
		firmware-name = "postmarketos/a660_zap.mbn";
	};
};

&gmu {
	firmware-name = "postmarketos/a660_gmu.bin";
};

&dispcc {
	status = "okay";
};

&mdss {
	status = "okay";
};

&mdss_dp {
	status = "okay";
};

&mdss_dsi0 {
	vdda-supply = <&pm8350_l6>;

	status = "okay";

	/* Common properties for OnePlus 9 and 9 Pro */
	display_panel: panel@0 {
		reg = <0>;

		vdd-supply = <&pm8350c_l13>;
		vddio-supply = <&pm8350c_l12>;
		avdd-supply = <&display_panel_avdd>;

		reset-gpios = <&tlmm 24 GPIO_ACTIVE_LOW>;

		pinctrl-0 = <&sde_dsi_active &sde_te_active>;
		pinctrl-1 = <&sde_dsi_suspend &sde_te_suspend>;
		pinctrl-names = "default", "sleep";
		/*
		/delete-property/ interconnects;
		/delete-property/ interconnect-names;
		*/
		//clocks = <&rpmhcc RPMH_DIV_CLK1>;
		//clock-names = "div_clk";
		//clocks = <&mdss_dsi0_phy DISP_CC_MDSS_>

		status = "disabled";

		port {
			panel_in: endpoint {
				remote-endpoint = <&mdss_dsi0_out>;
			};
		};
	};
};

&mdss_dsi0_out {
	remote-endpoint = <&panel_in>;
	data-lanes = <0 1 2 3>;
};

&mdss_dsi0_phy {
	vdds-supply = <&pm8350_l5>;

	status = "okay";
};
/*
&mdss_dsi1 {
	vdda-supply = <&pm8350_l6>;

	status = "okay";
};

&mdss_dsi1_phy {
	vdds-supply = <&pm8350_l5>;
};
*/
